# STM32F102x6 register map
File version: 1.0
Registers are 32-bit, read-write, reset 0x0 unless marked. A register's access mark holds for its fields unless they carry their own. Offsets are from the block's base; [hi:lo] are bit positions; {n}, {i} and the like mark numbered series; 'fields as' and 'values as' point back to an identical list.

## USB — Universal Serial Bus Full Speed Device
Base 0x40005C00
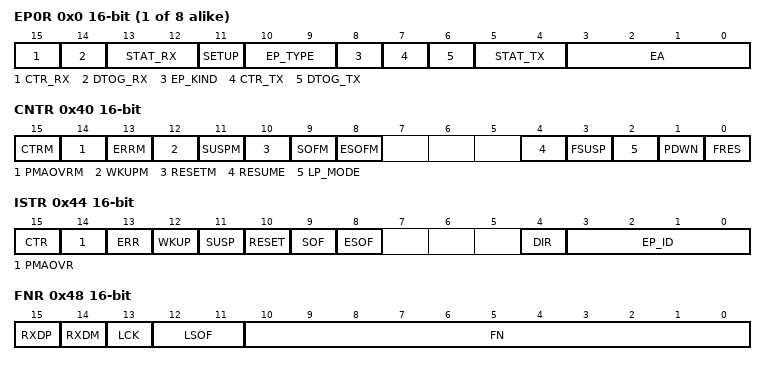
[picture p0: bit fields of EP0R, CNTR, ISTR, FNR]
{0x0+4i} EP{i}R 16-bit (i=0..7) — USB Endpoint {i} register
  [15] CTR_RX — Correct Transfer for reception
  [14] DTOG_RX — Data Toggle, for reception transfers
  [13:12] STAT_RX — STAT_RX[1:0] bits (Status bits, for reception transfers)
  [11] SETUP — Setup transaction completed
  [10:9] EP_TYPE — EP_TYPE[1:0] bits (Endpoint type)
  [8] EP_KIND — Endpoint Kind
  [7] CTR_TX — Correct Transfer for transmission
  [6] DTOG_TX — Data Toggle, for transmission transfers
  [5:4] STAT_TX — STAT_TX[1:0] bits (Status bits, for transmission transfers)
  [3:0] EA — Endpoint Address
0x40 CNTR 16-bit — Control register
  [15] CTRM — Correct Transfer Interrupt Mask
  [14] PMAOVRM — Packet Memory Area Over / Underrun Interrupt Mask
  [13] ERRM — Error Interrupt Mask
  [12] WKUPM — Wakeup Interrupt Mask
  [11] SUSPM — Suspend mode Interrupt Mask
  [10] RESETM — RESET Interrupt Mask
  [9] SOFM — Start Of Frame Interrupt Mask
  [8] ESOFM — Expected Start Of Frame Interrupt Mask
  [4] RESUME — Resume request
  [3] FSUSP — Force suspend
  [2] LP_MODE — Low-power mode
  [1] PDWN — Power down
  [0] FRES — Force USB Reset
0x44 ISTR 16-bit — Interrupt status register
  [15] CTR — Correct Transfer
  [14] PMAOVR — Packet Memory Area Over / Underrun
  [13] ERR — Error
  [12] WKUP — Wake up
  [11] SUSP — Suspend mode request
  [10] RESET — USB RESET request
  [9] SOF — Start Of Frame
  [8] ESOF — Expected Start Of Frame
  [4] DIR — Direction of transaction
  [3:0] EP_ID — Endpoint Identifier
0x48 FNR 16-bit — Frame number register
  [15] RXDP — Receive Data + Line Status
  [14] RXDM — Receive Data - Line Status
  [13] LCK — Locked
  [12:11] LSOF — Lost SOF
  [10:0] FN — Frame Number
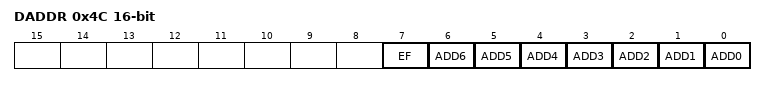
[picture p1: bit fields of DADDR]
0x4C DADDR 16-bit — Device address register
  [7] EF — Enable Function
  [n] ADD{n} (n=0..6) — Bit {n}
0x50 BTABLE 16-bit — Buffer Table address register
  [15:3] BTABLE — Buffer Table

## BKP — Backup Registers
Base 0x40006C00
{0x0+4i} DR{i} (i=1..10)
  [15:0] D — Backup data
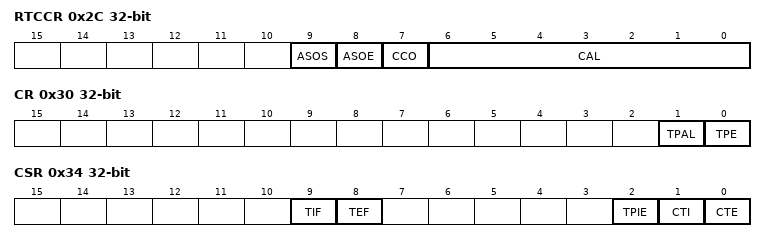
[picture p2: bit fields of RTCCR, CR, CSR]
0x2C RTCCR
  [9] ASOS — Alarm or Second Output Selection
  [8] ASOE — Alarm or Second Output Enable
  [7] CCO — Calibration Clock Output
  [6:0] CAL — Calibration value
0x30 CR
  [1] TPAL — TAMPER pin active level
    1=LOW (A high level on the TAMPER pin resets all data backup registers (if TPE bit is set)); 0=HIGH (A low level on the TAMPER pin resets all data backup registers (if TPE bit is set))
  [0] TPE — TAMPER pin enable
0x34 CSR
  [9] TIF — Tamper Interrupt Flag
  [8] TEF — Tamper Event Flag
  [2] TPIE — TAMPER Pin interrupt enable
  [1] CTI — Clear Tamper Interrupt
  [0] CTE — Clear Tamper event

## PWR — Power Control
Base 0x40007000
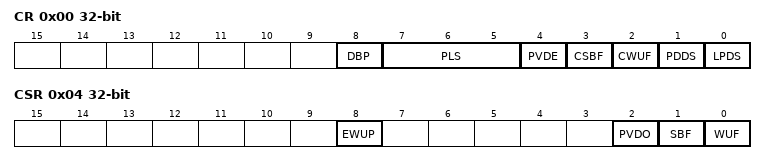
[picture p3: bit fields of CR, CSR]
0x00 CR
  [8] DBP — Disable Backup Domain write protection
  [7:5] PLS — PLS[2:0] bits (PVD Level Selection)
    0=PVDLEVEL_0 (Voltage threshold detected by PVD 2.2 V); 1=PVDLEVEL_1 (Voltage threshold detected by PVD 2.3 V); 2=PVDLEVEL_2 (Voltage threshold detected by PVD 2.4 V); 3=PVDLEVEL_3 (Voltage threshold detected by PVD 2.5 V); 4=PVDLEVEL_4 (Voltage threshold detected by PVD 2.6 V); 5=PVDLEVEL_5 (Voltage threshold detected by PVD 2.7 V); 6=PVDLEVEL_6 (Voltage threshold detected by PVD 2.8 V); 7=PVDLEVEL_7 (Voltage threshold detected by PVD 2.9 V)
  [4] PVDE — Power Voltage Detector Enable
  [3] CSBF — Clear Standby Flag
  [2] CWUF — Clear Wakeup Flag
  [1] PDDS — Power Down Deepsleep
  [0] LPDS — Low-Power Deepsleep
    0=MAIN (Voltage Regulator in main mode during deepsleep mode); 1=LOW_POWER (Voltage Regulator in low-power mode during deepsleep mode)
0x04 CSR
  [8] EWUP — Enable WKUP pin
  [2] PVDO — PVD Output
  [1] SBF — Standby Flag
  [0] WUF — Wakeup Flag

## AFIO — Alternate Function I/O
Base 0x40010000
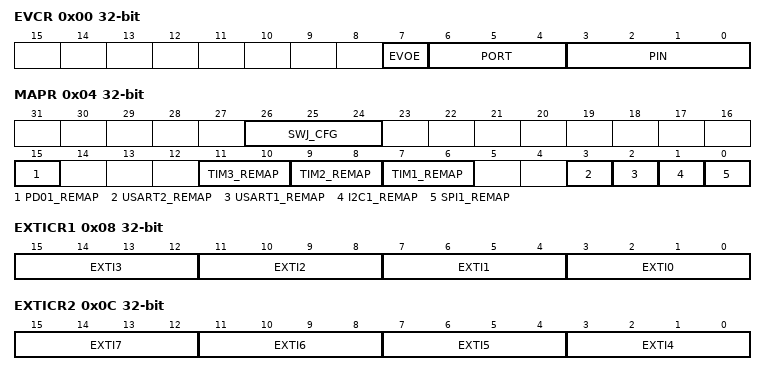
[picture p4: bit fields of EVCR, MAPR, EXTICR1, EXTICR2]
0x00 EVCR
  [7] EVOE — Event Output Enable
  [6:4] PORT — PORT[2:0] bits (Port selection)
  [3:0] PIN — PIN[3:0] bits (Pin selection)
0x04 MAPR
  [26:24] SWJ_CFG — SWJ_CFG[2:0] bits (Serial Wire JTAG configuration)
  [15] PD01_REMAP — Port D0/Port D1 mapping on OSC_IN/OSC_OUT
  [11:10] TIM3_REMAP — TIM3_REMAP[1:0] bits (TIM3 remapping)
  [9:8] TIM2_REMAP — TIM2_REMAP[1:0] bits (TIM2 remapping)
  [7:6] TIM1_REMAP — TIM1_REMAP[1:0] bits (TIM1 remapping)
  [3] USART2_REMAP — USART2 remapping
  [2] USART1_REMAP — USART1 remapping
  [1] I2C1_REMAP — I2C1 remapping
  [0] SPI1_REMAP — SPI1 remapping
0x08 EXTICR1
  [4n+3:4n] EXTI{n} (n=0..3) — EXTI {n} configuration
0x0C EXTICR2
  [4n-13:4n-16] EXTI{n} (n=4..7) — EXTI {n} configuration
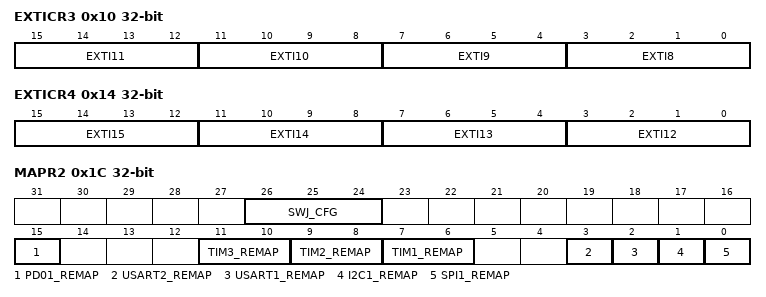
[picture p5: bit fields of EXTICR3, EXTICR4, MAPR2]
0x10 EXTICR3
  [4n-29:4n-32] EXTI{n} (n=8..11) — EXTI {n} configuration
0x14 EXTICR4
  [4n-45:4n-48] EXTI{n} (n=12..15) — EXTI {n} configuration
0x1C MAPR2
  fields as MAPR
